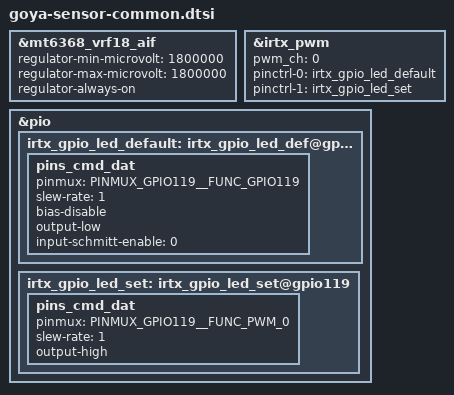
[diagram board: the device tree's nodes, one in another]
/* sx9373 power start */
&mt6368_vrf18_aif {
	regulator-min-microvolt = <1800000>;
	regulator-max-microvolt = <1800000>;
	regulator-always-on;
};
/* sx9373 power end */

/* GPIO IRTX start */
&irtx_pwm {
	pwm_ch = <0>;
	pinctrl-names = "irtx_gpio_led_default", "irtx_gpio_led_set";
	pinctrl-0 = <&irtx_gpio_led_default>;
	pinctrl-1 = <&irtx_gpio_led_set>;
	status = "okay";
};

&pio {
	/* IRTX GPIO Settings -Start */
	/* default: GPIO0, output, high */
	irtx_gpio_led_default:irtx_gpio_led_def@gpio119 {
		pins_cmd_dat {
			pinmux = <PINMUX_GPIO119__FUNC_GPIO119>;
			slew-rate = <1>;
			bias-disable;
			output-low;
			input-schmitt-enable = <0>;
		};
	};
	irtx_gpio_led_set:irtx_gpio_led_set@gpio119 {
		pins_cmd_dat {
			pinmux = <PINMUX_GPIO119__FUNC_PWM_0>;
			slew-rate = <1>;
			output-high;
		};
	};
};
/* GPIO IRTX end */
